# JPGENC0_CORE register map
Vendor: Texas Instruments
Peripheral module from a debugger description file (folder am62A).
Registers are 32-bit, read-write, reset 0x0 unless marked. A register's access mark holds for its fields unless they carry their own. Offsets are as the file gives them; lines under a group give offsets from that group; [hi:lo] are bit positions; {n}, {i} and the like mark numbered series; 'fields as' and 'values as' point back to an identical list; <NAME> marks a mode.

## JPGENC0_CORE
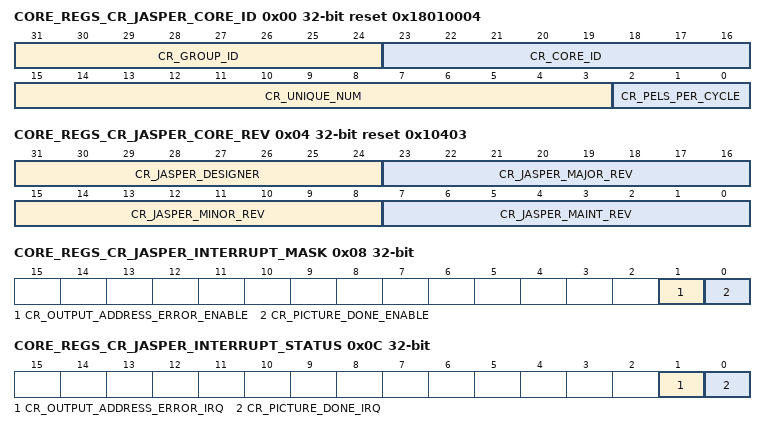
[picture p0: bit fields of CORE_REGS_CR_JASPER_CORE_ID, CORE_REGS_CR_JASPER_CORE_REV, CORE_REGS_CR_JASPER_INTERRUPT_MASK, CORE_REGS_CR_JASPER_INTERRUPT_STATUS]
0x00 CORE_REGS_CR_JASPER_CORE_ID ro reset 0x18010004
  [31:24] CR_GROUP_ID — This identifies the core as part of an IMG IP family group.
  [23:16] CR_CORE_ID — This identifies the member of the IP group.
  [15:3] CR_UNIQUE_NUM — E5010 core unique identifier.
  [2:0] CR_PELS_PER_CYCLE — Number of pels processed simultaneously. Allowed values are '010' and '100'.
0x04 CORE_REGS_CR_JASPER_CORE_REV ro reset 0x10403
  [31:24] CR_JASPER_DESIGNER — Company ID [Allocated by IMG].
  [23:16] CR_JASPER_MAJOR_REV — Core major revision.
  [15:8] CR_JASPER_MINOR_REV — Core minor revision.
  [7:0] CR_JASPER_MAINT_REV — Core maintenance revision.
0x08 CORE_REGS_CR_JASPER_INTERRUPT_MASK access per field
  [1] CR_OUTPUT_ADDRESS_ERROR_ENABLE rw — Enable generation of output address error interrupt.
  [0] CR_PICTURE_DONE_ENABLE rw — Enable generation of PICTURE_DONE interrupt.
0x0C CORE_REGS_CR_JASPER_INTERRUPT_STATUS ro
  [1] CR_OUTPUT_ADDRESS_ERROR_IRQ — Output bitstream size exceeded value stored in CR_JASPER_OUTPUT_MAX_SIZE register. [Pulse generated at event, held by edge detection logic].
  [0] CR_PICTURE_DONE_IRQ — Processing of picture is done. [Pulse generated at event, held by edge detection logic].
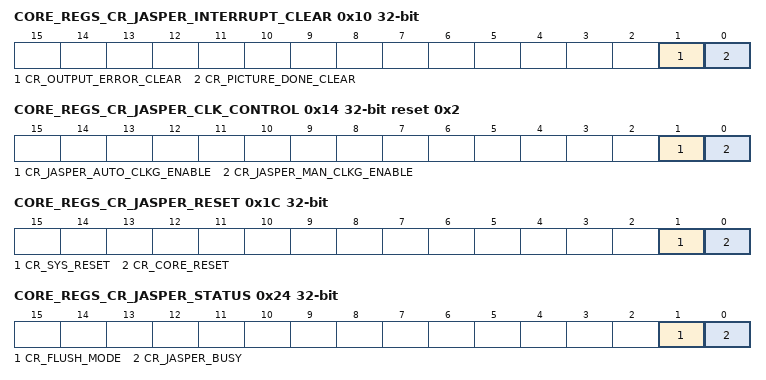
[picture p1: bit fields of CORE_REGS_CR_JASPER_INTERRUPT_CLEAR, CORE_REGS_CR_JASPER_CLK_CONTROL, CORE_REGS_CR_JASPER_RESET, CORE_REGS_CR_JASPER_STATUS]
0x10 CORE_REGS_CR_JASPER_INTERRUPT_CLEAR wo
  [1] CR_OUTPUT_ERROR_CLEAR — Writing '1' to this field clears OUTPUT_ADDRESS_ERROR flag [JASPER_INTERRUPT_STATUS register]. This field is self-clear. When read, it will always return zero.
  [0] CR_PICTURE_DONE_CLEAR — Writing '1' to this field clears PICTURE_DONE_IRQ flag [JASPER_INTERRUPT_STATUS register]. This field is self-clear. When read, it will always return zero.
0x14 CORE_REGS_CR_JASPER_CLK_CONTROL access per field reset 0x2
  [1] CR_JASPER_AUTO_CLKG_ENABLE rw — 0: disable auto clock gating 1: enable auto clock gating
  [0] CR_JASPER_MAN_CLKG_ENABLE rw — Writing '1' to this field enables clocking of the E5010 core.
0x18 CORE_REGS_CR_JASPER_CLK_STATUS ro
  [0] CR_JASPER_CLKG_STATUS — Indicates the clock gate status 1: clock gating is off 0: clock gating is on
0x1C CORE_REGS_CR_JASPER_RESET wo
  [1] CR_SYS_RESET — When set forces a reset of the whole IP. It is self-cleared.
  [0] CR_CORE_RESET — When set forces a reset of the core modules except the core registers. It is self-cleared.
0x20 CORE_REGS_CR_JASPER_CORE_CTRL access per field
  [0] CR_JASPER_ENCODE_START rw — This bit can be written only when JASPER_BUSY flag is set to '0' [JASPER_CORE_STATUS register. Writing '1' forces E5010 to start encoding of an image and sets JASPER_BUSY flag to '1'. Writing '0' has no effect. This bit is self-clear. When read, it will always return zero.
0x24 CORE_REGS_CR_JASPER_STATUS ro
  [1] CR_FLUSH_MODE — This field has value '1' when output address error occurred [output bitstream size exceeded value stored in CR_JASPER_OUTPUT_MAX_SIZE register]. It is self-cleared after recovering from the error state.
  [0] CR_JASPER_BUSY — When set up it indicates pending encoding process. It is automatically cleared after image encoding process finishes if image source is memory. In case of stream encoding, this flag is cleared after a single frame has been encoded.
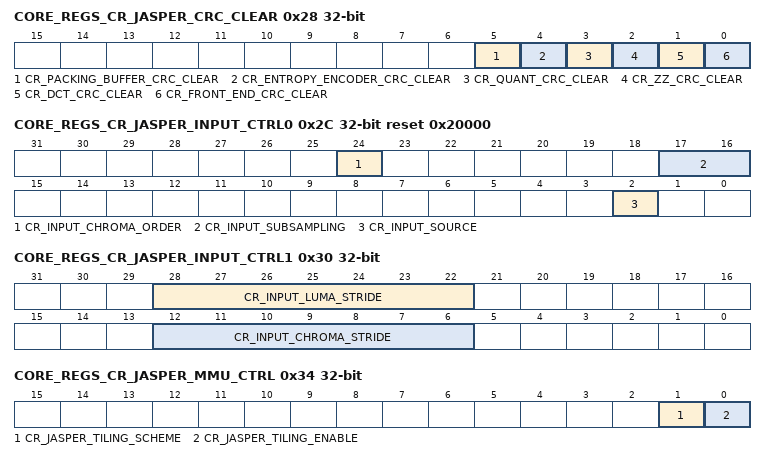
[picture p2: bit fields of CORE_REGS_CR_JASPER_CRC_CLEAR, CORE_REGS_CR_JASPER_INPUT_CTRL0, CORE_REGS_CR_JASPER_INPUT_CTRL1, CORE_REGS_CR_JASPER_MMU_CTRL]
0x28 CORE_REGS_CR_JASPER_CRC_CLEAR wo — Active high resets for the CRCs. CRCs are cleared on writing the relevant bit of this register to '1'. The register bit will then self-clear. When read, this register will always return zero.
  [5] CR_PACKING_BUFFER_CRC_CLEAR — 0 : Has no effect 1 : Clear Packing buffer CRC
  [4] CR_ENTROPY_ENCODER_CRC_CLEAR — 0 : Has no effect 1 : Clear Entropy encoder CRC
  [3] CR_QUANT_CRC_CLEAR — 0 : Has no effect 1 : Clear Quantization block CRC
  [2] CR_ZZ_CRC_CLEAR — 0 : Has no effect 1 : Clear Zig-zag CRC
  [1] CR_DCT_CRC_CLEAR — 0 : Has no effect 1 : Clear DCT CRC
  [0] CR_FRONT_END_CRC_CLEAR — 0 : Has no effect 1 : Clear Front End CRC
0x2C CORE_REGS_CR_JASPER_INPUT_CTRL0 access per field reset 0x20000
  [24] CR_INPUT_CHROMA_ORDER rw — Defines order of interleaved chroma pels in memory '0': chroma data in order Cb-Cr '1': chroma data in order Cr-Cb
  [17:16] CR_INPUT_SUBSAMPLING rw — Chroma subsampling format. 0x00: Reserved 0x01: 4:2:0 0x02: 4:2:2 0x03: Reserved
  [2] CR_INPUT_SOURCE rw — Input data source. 0: direct 1: memory
0x30 CORE_REGS_CR_JASPER_INPUT_CTRL1 access per field
  [28:22] CR_INPUT_LUMA_STRIDE rw — Width of pixels' line of luma data in memory; multiples of 64 bytes. 0 denotes maximum value - 128x64 B
  [12:6] CR_INPUT_CHROMA_STRIDE rw — Width of pixels' line of chroma data in memory; multiples of 64 bytes. 0 denotes maximum value - 128x64 B
0x34 CORE_REGS_CR_JASPER_MMU_CTRL access per field — Setting this register is applicable only when processing image from system memory.
  [1] CR_JASPER_TILING_SCHEME rw — Tiling scheme 0 = 256x16, 1 = 512*8. This bit must be set to the same value as MMU_TILING_SCHEME in MMU_CONTROL0 register [see IMG_VIDEO_BUS4_MMU registers].
  [0] CR_JASPER_TILING_ENABLE rw — Indicates that memory tiling in the MMU is enabled. Should be set to the same value as TILE_ENABLE bit in MMU_TILE_CFGn register [see IMG_VIDEO_BUS4_MMU registers]. NOTE: Memory tiling inside the E5010 core can be applied to input data only [output stream is always untiled] and is always the same for luma and chroma data [cannot be set up individually for both color planes]. Tiling region[s] should be configured correctly in IMG_VIDEO_BUS4_MMU registers: MMU_CONTROL0, MMU_TILE_CFGn, MMU_TILE_MIN_ADDRn and MMU_TILE_MAX_ADDRn.
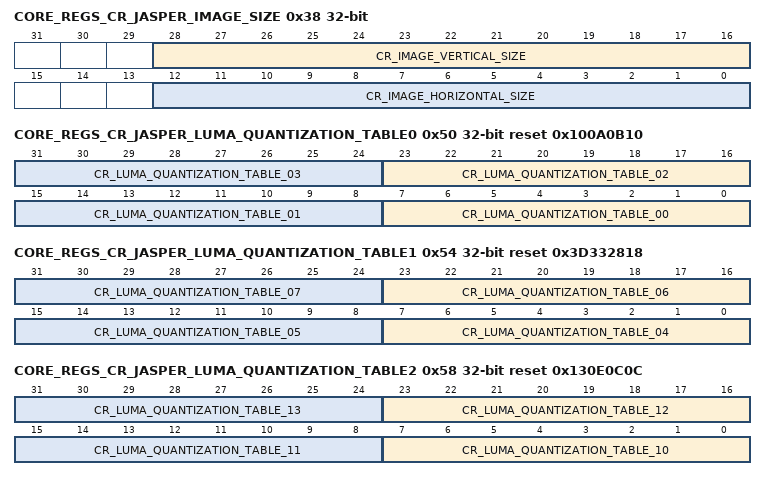
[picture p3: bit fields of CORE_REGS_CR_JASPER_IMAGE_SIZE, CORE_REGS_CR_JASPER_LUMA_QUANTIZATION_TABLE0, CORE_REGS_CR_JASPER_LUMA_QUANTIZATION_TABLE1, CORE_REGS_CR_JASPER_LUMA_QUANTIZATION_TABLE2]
0x38 CORE_REGS_CR_JASPER_IMAGE_SIZE access per field
  [28:16] CR_IMAGE_VERTICAL_SIZE rw — Number of lines in an image - 1.
  [12:0] CR_IMAGE_HORIZONTAL_SIZE rw — Number of pixels per line - 1.
0x3C CORE_REGS_CR_INPUT_LUMA_BASE access per field
  [31:6] CR_INPUT_LUMA_BASE rw — Address of input luma data. Aligned to 64 bytes.
0x40 CORE_REGS_CR_INPUT_CHROMA_BASE access per field
  [31:6] CR_INPUT_CHROMA_BASE rw — Address of input chroma data. Aligned to 64 bytes.
0x44 CORE_REGS_CR_JASPER_OUTPUT_BASE
  [31:0] CR_OUTPUT_BASE — Base address for output bitstream.
0x48 CORE_REGS_CR_JASPER_OUTPUT_SIZE ro — Set when image processing is done (busy flag transits from 1 to 0). Cleared automatically after start of next frame compression.
  [31:0] CR_OUTPUT_SIZE — Output bitstream size in bytes.
0x4C CORE_REGS_CR_JASPER_OUTPUT_MAX_SIZE
  [31:0] CR_OUTPUT_MAX_SIZE — Maximum size of output bitstream. Should be set to the size of allocated memory. If set to 0 address checking is disabled.
0x50 CORE_REGS_CR_JASPER_LUMA_QUANTIZATION_TABLE0 reset 0x100A0B10 — Luma quantization table entries QL03..QL00
  [8n+7:8n] CR_LUMA_QUANTIZATION_TABLE_{n:02} (n=0..3) — QL{n:02}
0x54 CORE_REGS_CR_JASPER_LUMA_QUANTIZATION_TABLE1 reset 0x3D332818 — QL07..QL04
  [8n-25:8n-32] CR_LUMA_QUANTIZATION_TABLE_{n:02} (n=4..7) — QL{n:02}
0x58 CORE_REGS_CR_JASPER_LUMA_QUANTIZATION_TABLE2 reset 0x130E0C0C — QL13..QL10
  [8n-73:8n-80] CR_LUMA_QUANTIZATION_TABLE_{n} (n=10..13) — QL{n}
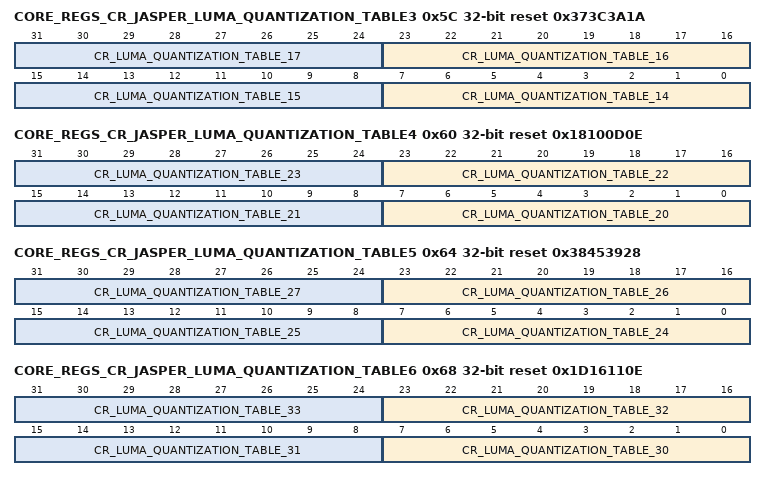
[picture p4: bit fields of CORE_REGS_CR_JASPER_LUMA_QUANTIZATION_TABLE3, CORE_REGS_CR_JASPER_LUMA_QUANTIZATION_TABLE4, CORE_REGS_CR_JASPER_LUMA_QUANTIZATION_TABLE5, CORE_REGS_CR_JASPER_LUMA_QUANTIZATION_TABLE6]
0x5C CORE_REGS_CR_JASPER_LUMA_QUANTIZATION_TABLE3 reset 0x373C3A1A — QL17..QL14
  [8n-105:8n-112] CR_LUMA_QUANTIZATION_TABLE_{n} (n=14..17) — QL{n}
0x60 CORE_REGS_CR_JASPER_LUMA_QUANTIZATION_TABLE4 reset 0x18100D0E — QL23..QL20
  [8n-153:8n-160] CR_LUMA_QUANTIZATION_TABLE_{n} (n=20..23) — QL{n}
0x64 CORE_REGS_CR_JASPER_LUMA_QUANTIZATION_TABLE5 reset 0x38453928 — QL27..QL24
  [8n-185:8n-192] CR_LUMA_QUANTIZATION_TABLE_{n} (n=24..27) — QL{n}
0x68 CORE_REGS_CR_JASPER_LUMA_QUANTIZATION_TABLE6 reset 0x1D16110E — QL33..QL30
  [8n-233:8n-240] CR_LUMA_QUANTIZATION_TABLE_{n} (n=30..33) — QL{n}
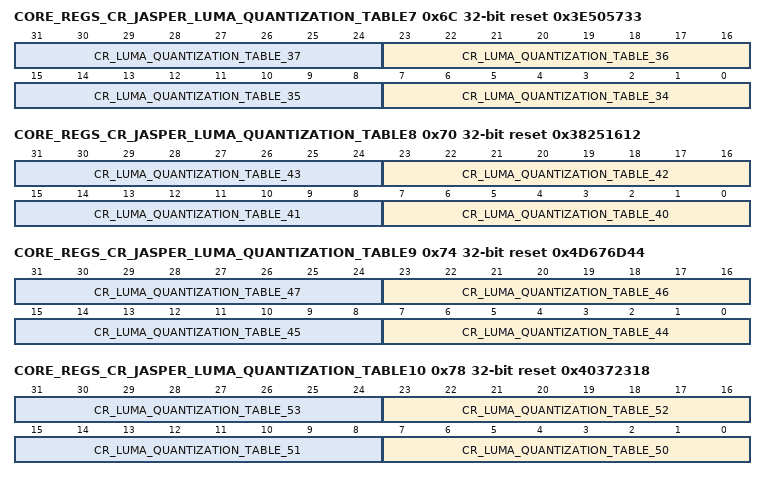
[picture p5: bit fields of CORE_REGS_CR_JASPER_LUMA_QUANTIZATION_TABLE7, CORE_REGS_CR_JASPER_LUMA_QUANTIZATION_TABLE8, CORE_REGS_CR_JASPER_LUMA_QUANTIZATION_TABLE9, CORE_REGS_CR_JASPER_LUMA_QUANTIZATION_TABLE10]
0x6C CORE_REGS_CR_JASPER_LUMA_QUANTIZATION_TABLE7 reset 0x3E505733 — QL37..QL34
  [8n-265:8n-272] CR_LUMA_QUANTIZATION_TABLE_{n} (n=34..37) — QL{n}
0x70 CORE_REGS_CR_JASPER_LUMA_QUANTIZATION_TABLE8 reset 0x38251612 — QL43..QL40
  [8n-313:8n-320] CR_LUMA_QUANTIZATION_TABLE_{n} (n=40..43) — QL{n}
0x74 CORE_REGS_CR_JASPER_LUMA_QUANTIZATION_TABLE9 reset 0x4D676D44 — QL47..QL44
  [8n-345:8n-352] CR_LUMA_QUANTIZATION_TABLE_{n} (n=44..47) — QL{n}
0x78 CORE_REGS_CR_JASPER_LUMA_QUANTIZATION_TABLE10 reset 0x40372318 — QL53..QL50
  [8n-393:8n-400] CR_LUMA_QUANTIZATION_TABLE_{n} (n=50..53) — QL{n}
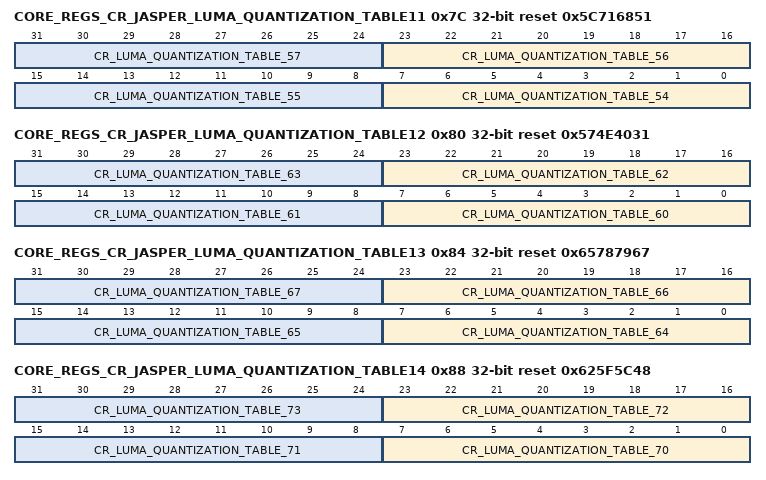
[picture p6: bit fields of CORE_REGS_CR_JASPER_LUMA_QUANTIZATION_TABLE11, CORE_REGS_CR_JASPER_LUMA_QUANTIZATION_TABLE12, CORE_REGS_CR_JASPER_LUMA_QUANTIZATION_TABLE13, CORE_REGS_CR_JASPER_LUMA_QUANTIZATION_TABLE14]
0x7C CORE_REGS_CR_JASPER_LUMA_QUANTIZATION_TABLE11 reset 0x5C716851 — QL57..QL54
  [8n-425:8n-432] CR_LUMA_QUANTIZATION_TABLE_{n} (n=54..57) — QL{n}
0x80 CORE_REGS_CR_JASPER_LUMA_QUANTIZATION_TABLE12 reset 0x574E4031 — QL63..QL60
  [8n-473:8n-480] CR_LUMA_QUANTIZATION_TABLE_{n} (n=60..63) — QL{n}
0x84 CORE_REGS_CR_JASPER_LUMA_QUANTIZATION_TABLE13 reset 0x65787967 — QL67..QL64
  [8n-505:8n-512] CR_LUMA_QUANTIZATION_TABLE_{n} (n=64..67) — QL{n}
0x88 CORE_REGS_CR_JASPER_LUMA_QUANTIZATION_TABLE14 reset 0x625F5C48 — QL73..QL70
  [8n-553:8n-560] CR_LUMA_QUANTIZATION_TABLE_{n} (n=70..73) — QL{n}
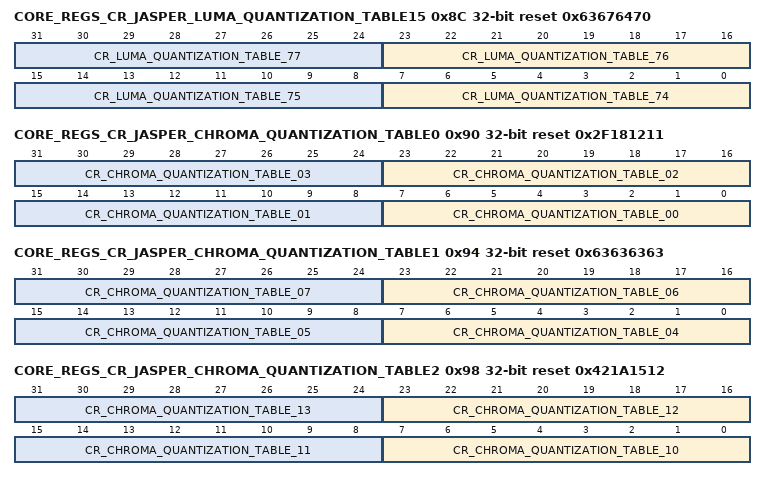
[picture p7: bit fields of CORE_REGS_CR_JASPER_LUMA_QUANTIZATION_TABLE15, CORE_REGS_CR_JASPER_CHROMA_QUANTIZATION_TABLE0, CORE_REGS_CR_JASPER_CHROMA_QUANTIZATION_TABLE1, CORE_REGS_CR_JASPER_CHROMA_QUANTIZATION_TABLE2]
0x8C CORE_REGS_CR_JASPER_LUMA_QUANTIZATION_TABLE15 reset 0x63676470 — QL77..QL74
  [8n-585:8n-592] CR_LUMA_QUANTIZATION_TABLE_{n} (n=74..77) — QL{n}
0x90 CORE_REGS_CR_JASPER_CHROMA_QUANTIZATION_TABLE0 reset 0x2F181211 — Chroma quantization table entries QC03..QC00
  [8n+7:8n] CR_CHROMA_QUANTIZATION_TABLE_{n:02} (n=0..3) — QC{n:02}
0x94 CORE_REGS_CR_JASPER_CHROMA_QUANTIZATION_TABLE1 reset 0x63636363 — QC07..QC04
  [8n-25:8n-32] CR_CHROMA_QUANTIZATION_TABLE_{n:02} (n=4..7) — QC{n:02}
0x98 CORE_REGS_CR_JASPER_CHROMA_QUANTIZATION_TABLE2 reset 0x421A1512 — QC13..QC10
  [8n-73:8n-80] CR_CHROMA_QUANTIZATION_TABLE_{n} (n=10..13) — QC{n}
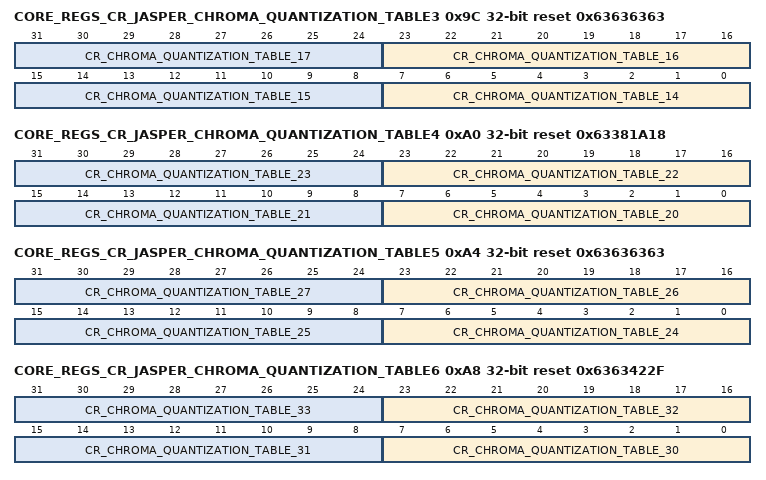
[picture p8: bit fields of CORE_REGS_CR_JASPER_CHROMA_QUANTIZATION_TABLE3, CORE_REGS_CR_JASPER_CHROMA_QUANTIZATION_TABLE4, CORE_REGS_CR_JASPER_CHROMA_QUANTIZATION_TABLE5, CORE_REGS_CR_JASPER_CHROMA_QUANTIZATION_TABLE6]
0x9C CORE_REGS_CR_JASPER_CHROMA_QUANTIZATION_TABLE3 reset 0x63636363 — QC17..QC14
  [8n-105:8n-112] CR_CHROMA_QUANTIZATION_TABLE_{n} (n=14..17) — QC{n}
0xA0 CORE_REGS_CR_JASPER_CHROMA_QUANTIZATION_TABLE4 reset 0x63381A18 — QC23..QC20
  [8n-153:8n-160] CR_CHROMA_QUANTIZATION_TABLE_{n} (n=20..23) — QC{n}
0xA4 CORE_REGS_CR_JASPER_CHROMA_QUANTIZATION_TABLE5 reset 0x63636363 — QC27..QC24
  [8n-185:8n-192] CR_CHROMA_QUANTIZATION_TABLE_{n} (n=24..27) — QC{n}
0xA8 CORE_REGS_CR_JASPER_CHROMA_QUANTIZATION_TABLE6 reset 0x6363422F — QC33..QC30
  [8n-233:8n-240] CR_CHROMA_QUANTIZATION_TABLE_{n} (n=30..33) — QC{n}
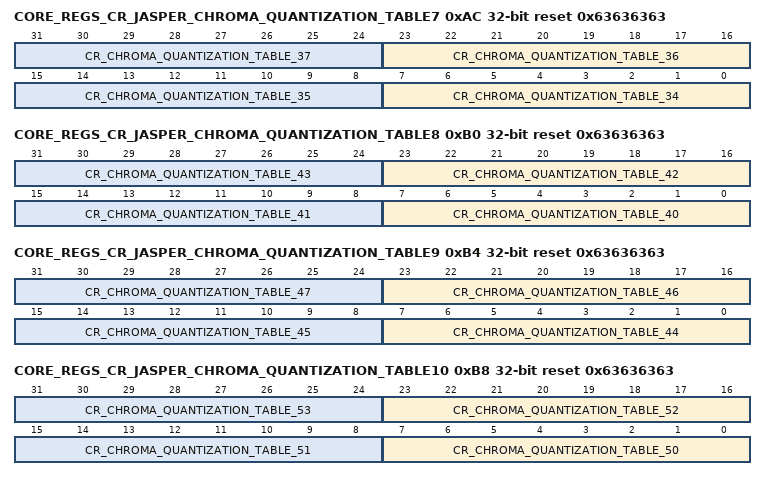
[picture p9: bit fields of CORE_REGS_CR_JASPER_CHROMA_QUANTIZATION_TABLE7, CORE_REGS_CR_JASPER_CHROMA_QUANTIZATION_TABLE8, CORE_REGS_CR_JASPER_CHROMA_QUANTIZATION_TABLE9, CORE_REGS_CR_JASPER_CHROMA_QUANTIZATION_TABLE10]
0xAC CORE_REGS_CR_JASPER_CHROMA_QUANTIZATION_TABLE7 reset 0x63636363 — QC37..QC34
  [8n-265:8n-272] CR_CHROMA_QUANTIZATION_TABLE_{n} (n=34..37) — QC{n}
0xB0 CORE_REGS_CR_JASPER_CHROMA_QUANTIZATION_TABLE8 reset 0x63636363 — QC43..QC40
  [8n-313:8n-320] CR_CHROMA_QUANTIZATION_TABLE_{n} (n=40..43) — QC{n}
0xB4 CORE_REGS_CR_JASPER_CHROMA_QUANTIZATION_TABLE9 reset 0x63636363 — QC47..QC44
  [8n-345:8n-352] CR_CHROMA_QUANTIZATION_TABLE_{n} (n=44..47) — QC{n}
0xB8 CORE_REGS_CR_JASPER_CHROMA_QUANTIZATION_TABLE10 reset 0x63636363 — QC53..QC50
  [8n-393:8n-400] CR_CHROMA_QUANTIZATION_TABLE_{n} (n=50..53) — QC{n}
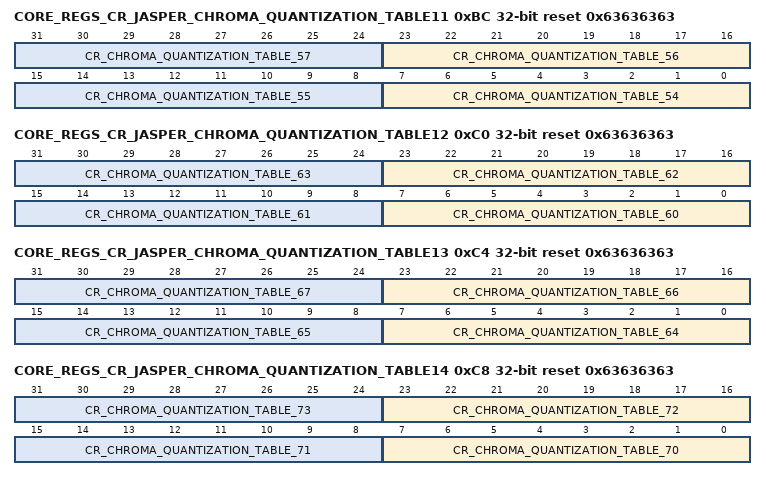
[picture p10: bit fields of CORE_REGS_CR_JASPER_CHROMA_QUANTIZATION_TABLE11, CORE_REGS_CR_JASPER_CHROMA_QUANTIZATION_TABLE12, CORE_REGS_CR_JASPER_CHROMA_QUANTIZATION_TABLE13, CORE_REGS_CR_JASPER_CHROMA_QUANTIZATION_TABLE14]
0xBC CORE_REGS_CR_JASPER_CHROMA_QUANTIZATION_TABLE11 reset 0x63636363 — QC57..QC54
  [8n-425:8n-432] CR_CHROMA_QUANTIZATION_TABLE_{n} (n=54..57) — QC{n}
0xC0 CORE_REGS_CR_JASPER_CHROMA_QUANTIZATION_TABLE12 reset 0x63636363 — QC63..QC60
  [8n-473:8n-480] CR_CHROMA_QUANTIZATION_TABLE_{n} (n=60..63) — QC{n}
0xC4 CORE_REGS_CR_JASPER_CHROMA_QUANTIZATION_TABLE13 reset 0x63636363 — QC67..QC64
  [8n-505:8n-512] CR_CHROMA_QUANTIZATION_TABLE_{n} (n=64..67) — QC{n}
0xC8 CORE_REGS_CR_JASPER_CHROMA_QUANTIZATION_TABLE14 reset 0x63636363 — QC73..QC70
  [8n-553:8n-560] CR_CHROMA_QUANTIZATION_TABLE_{n} (n=70..73) — QC{n}
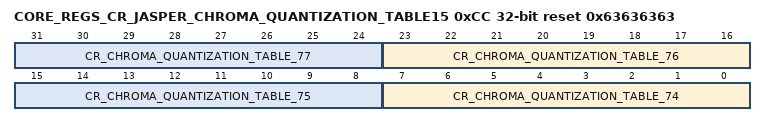
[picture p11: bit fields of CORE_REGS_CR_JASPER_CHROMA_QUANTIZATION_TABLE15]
0xCC CORE_REGS_CR_JASPER_CHROMA_QUANTIZATION_TABLE15 reset 0x63636363 — QC77..QC74
  [8n-585:8n-592] CR_CHROMA_QUANTIZATION_TABLE_{n} (n=74..77) — QC{n}
0xD0 CORE_REGS_CR_JASPER_CRC_CTRL access per field
  [0] JASPER_CRC_ENABLE rw — Writing '1' to this field enables CRC calculation.
0xD4 CORE_REGS_CR_JASPER_FRONT_END_CRC ro
  [31:0] CR_JASPER_FRONT_END_CRC_OUT — CRC value of the current data.
0xD8 CORE_REGS_CR_JASPER_DCT_CRC ro
  [31:0] CR_JASPER_DCT_CRC_OUT — CRC value of the current data.
0xDC CORE_REGS_CR_JASPER_ZZ_CRC ro
  [31:0] CR_JASPER_ZZ_CRC_OUT — CRC value of the current data.
0xE0 CORE_REGS_CR_JASPER_QUANT_CRC ro
  [31:0] CR_JASPER_QUANT_CRC_OUT — CRC value of the current data. ang1045
0xE4 CORE_REGS_CR_JASPER_ENTROPY_ENCODER_CRC ro
  [31:0] CR_JASPER_ENTROPY_CRC_OUT — CRC value of the current data.
0xE8 CORE_REGS_CR_JASPER_PACKING_BUFFER_DATA_CRC ro
  [31:0] CR_JASPER_PACKING_DATA_CRC_OUT — CRC value of the current data.
0xEC CORE_REGS_CR_JASPER_PACKING_BUFFER_ADDR_CRC ro
  [31:0] CR_JASPER_PACKING_ADDR_OUT_CRC — CRC value of the current data.
